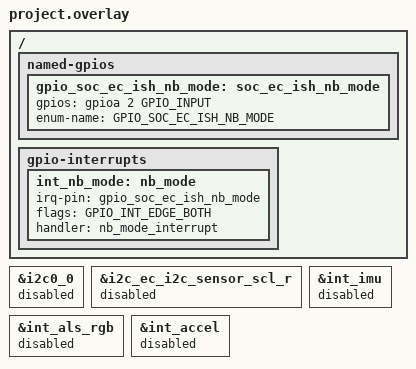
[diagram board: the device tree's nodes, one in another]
/* Copyright 2023 The ChromiumOS Authors
 * Use of this source code is governed by a BSD-style license that can be
 * found in the LICENSE file.
 */

/* Include base Rex */
#include "../rex/project.overlay"

&i2c0_0 {
	status = "disabled";
};
&i2c_ec_i2c_sensor_scl_r {
	status = "disabled";
};
&int_imu {
	status = "disabled";
};
&int_als_rgb {
	status = "disabled";
};
&int_accel {
	status = "disabled";
};

/ {
	named-gpios {
		gpio_soc_ec_ish_nb_mode: soc_ec_ish_nb_mode {
			gpios = <&gpioa 2 GPIO_INPUT>;
			enum-name = "GPIO_SOC_EC_ISH_NB_MODE";
		};
	};

	gpio-interrupts {
		int_nb_mode: nb_mode {
			irq-pin = <&gpio_soc_ec_ish_nb_mode>;
			flags = <GPIO_INT_EDGE_BOTH>;
			handler = "nb_mode_interrupt";
		};
	};
};
